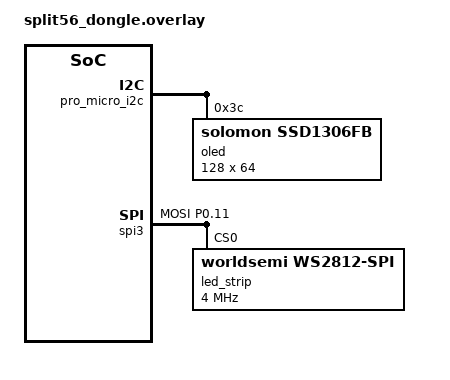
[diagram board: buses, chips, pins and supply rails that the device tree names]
/* Generated by tools/zmk_generate.py from pcb/pins.yaml and layout/generated/. Do not edit. */

/*
 * The desk dongle: the split central, with no keys of its own. Build it with the display
 * shield: "split56_dongle dongle_display".
 */

#include "split56.dtsi"
#include <dt-bindings/led/led.h>

/ {
    chosen {
        zmk,kscan = &mock_kscan;
        zephyr,display = &oled;
        zmk,underglow = &led_strip;
    };

    mock_kscan: mock_kscan_0 {
        compatible = "zmk,kscan-mock";
        columns = <0>;
        rows = <0>;
        events = <0>;
    };
};

/*
 * The common 0.96 in 128 x 64 SSD1306 I2C module (owner, 2026-11-23) on the Pro Micro I2C pins
 * (D2 SDA, D3 SCL). The properties are the usual ones for it: check them on the part.
 */
&pro_micro_i2c {
    status = "okay";

    oled: ssd1306@3c {
        compatible = "solomon,ssd1306fb";
        reg = <0x3c>;
        width = <128>;
        height = <64>;
        segment-offset = <0>;
        page-offset = <0>;
        display-offset = <0>;
        multiplex-ratio = <63>;
        segment-remap;
        com-invdir;
        inversion-on;
        prechargep = <0x22>;
    };
};

/* The one-LED strip that keeps the lighting behaviour on the central (see split56_dongle.conf). */
&pinctrl {
    spi3_default: spi3_default {
        group1 {
            psels = <NRF_PSEL(SPIM_MOSI, 0, 11)>;
        };
    };

    spi3_sleep: spi3_sleep {
        group1 {
            psels = <NRF_PSEL(SPIM_MOSI, 0, 11)>;
            low-power-enable;
        };
    };
};

&spi3 {
    compatible = "nordic,nrf-spim";
    status = "okay";

    pinctrl-0 = <&spi3_default>;
    pinctrl-1 = <&spi3_sleep>;
    pinctrl-names = "default", "sleep";

    led_strip: ws2812@0 {
        compatible = "worldsemi,ws2812-spi";

        /* SPI */
        reg = <0>; /* ignored, but necessary for SPI bindings */
        spi-max-frequency = <4000000>;

        /* SK6812MINI-E: WS2812 protocol, green first (datasheet) */
        chain-length = <1>;
        spi-one-frame = <0x70>;
        spi-zero-frame = <0x40>;
        color-mapping = <LED_COLOR_ID_GREEN LED_COLOR_ID_RED LED_COLOR_ID_BLUE>;
    };
};
